# V32F20x_CM33 register map
File version: 1.0.3
CPU: CM33 r0p4, little endian, MPU, FPU, DSP, 3 interrupt priority bits, 8 SAU regions
Registers are 32-bit, read-write, reset 0x0 unless marked. A register's access mark holds for its fields unless they carry their own. Offsets are from the block's base; [hi:lo] are bit positions.

## ETH0 — ETH0 Peripheral Interface
Base 0x40202000
Same registers: ETH1 0x40204000, SEC_ETH0 0x50202000, SEC_ETH1 0x50204000
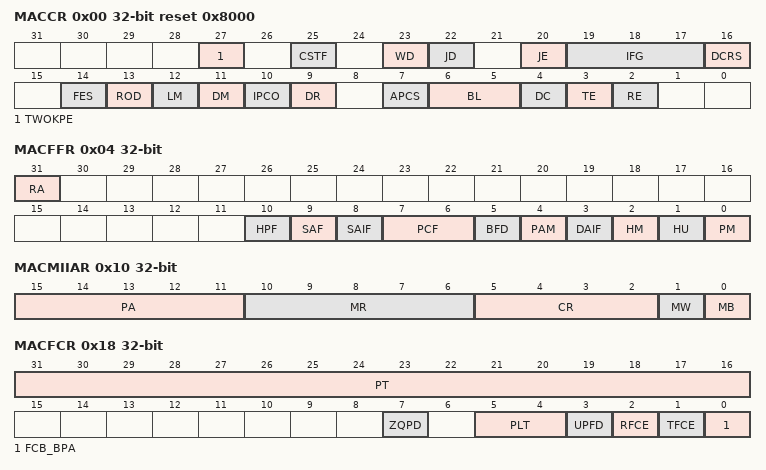
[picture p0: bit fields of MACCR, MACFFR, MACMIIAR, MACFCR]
0x00 MACCR reset 0x8000 — This is the operation mode register for the MAC.
  [27] TWOKPE — IEEE 802.3as Support for 2K Packets
  [25] CSTF — CRC Stripping for Type Frames
  [23] WD — Watchdog Disable
  [22] JD — Jabber Disable
  [20] JE — Jumbo Frame Enable
  [19:17] IFG — Inter-Frame Gap
  [16] DCRS — Disable Carrier Sense During Transmission
  [14] FES — Speed
  [13] ROD — Disable Receive Own
  [12] LM — Loopback Mode
  [11] DM — Duplex Mode
  [10] IPCO — Checksum Offload
  [9] DR — Disable Retry
  [7] APCS — Automatic Pad or CRC Stripping
  [6:5] BL — Back-Off Limit
  [4] DC — Deferral Check
  [3] TE — Transmitter Enable
  [2] RE — Receiver Enable
0x04 MACFFR — Contains the frame filtering controls.
  [31] RA — Receive All
  [10] HPF — Hash or Perfect Filter
  [9] SAF — Source Address Filter Enable
  [8] SAIF — SA Inverse Filtering
  [7:6] PCF — Pass Control Frames
  [5] BFD — Broadcast Frames Disable
  [4] PAM — Pass All Multicast
  [3] DAIF — DA Inverse Filtering
  [2] HM — Hash Multicast
  [1] HU — Hash Unicast
  [0] PM — Promiscuous Mode
0x08 MACHTHR — Contains the higher 32 bits of the Multicast Hash table
  [31:0] HTH — Hash Table High
0x0C MACHTLR — Contains the lower 32 bits of the Multicast Hash table
  [31:0] HTL — Hash Table Low
0x10 MACMIIAR — Controls the management cycles to an external PHY.
  [15:11] PA — Physical Layer Address
  [10:6] MR — MII Register
  [5:2] CR — Clock Range
  [1] MW — MII Write
  [0] MB — MII Busy
0x14 MACMIIDR — Contains the data to be written to or read from the PHY register
  [15:0] MD — MII Data
0x18 MACFCR — Controls the generation of control frames.
  [31:16] PT — Pause Time
  [7] ZQPD — Zero-Quanta Pause Disable
  [5:4] PLT — Pause Low Threshold
  [3] UPFD — Unicast Pause Frame Detect
  [2] RFCE — Receive Flow Control Enable
  [1] TFCE — Transmit Flow Control Enable
  [0] FCB_BPA — Flow Control Busy or Backpressure Activate
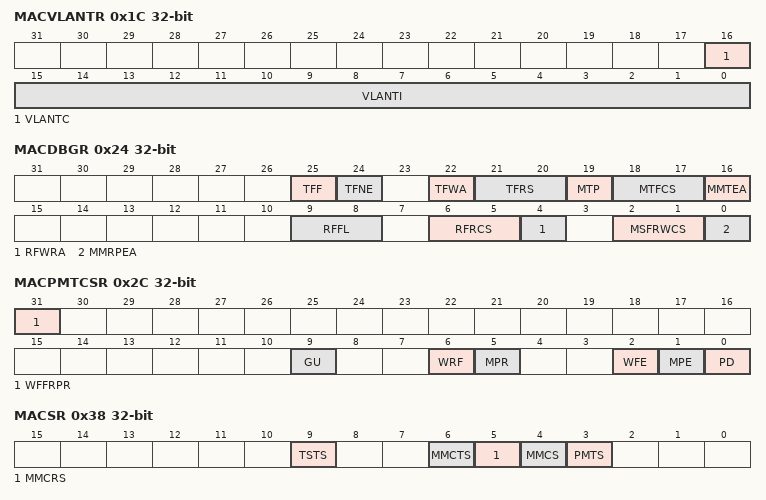
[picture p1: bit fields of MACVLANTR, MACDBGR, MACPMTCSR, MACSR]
0x1C MACVLANTR — Identifies IEEE 802.1Q VLAN type frames.
  [16] VLANTC — Enable 12-Bit VLAN Tag Comparison
  [15:0] VLANTI — VLAN Tag Identifier for Receive Frames
0x24 MACDBGR — Gives the status of various internal blocks for debugging
  [25] TFF — TxStatus FIFO Full Status
  [24] TFNE — Tx FIFO Not Empty Status
  [22] TFWA — Tx FIFO Write Controller Status
  [21:20] TFRS — Tx FIFO Read Controller Status
  [19] MTP — MAC Transmitter in Pause
  [18:17] MTFCS — MAC Transmit Frame Controller Status
  [16] MMTEA — MAC MII Transmit Protocol Engine Status
  [9:8] RFFL — RxFIFO Fill-Level Status
  [6:5] RFRCS — RxFIFO Read Controller State
  [4] RFWRA — Rx FIFO Write Controller Active Status
  [2:1] MSFRWCS — MAC Receive Frame FIFO Controller Status
  [0] MMRPEA — MAC MII Receive Protocol Engine Status
0x28 MACRWUFFR — This is the address through which the application writes or reads the remote wake-up frame filter registers
  [31:0] WF — Ethernet MAC remote wakeup frame filter register.
0x2C MACPMTCSR — Ethernet MAC PMT control and status register
  [31] WFFRPR — Wakeup frame filter register pointer reset
  [9] GU — Global unicast
  [6] WRF — Wakeup frame received
  [5] MPR — Magic packet received
  [2] WFE — Wakeup frame enable
  [1] MPE — Magic Packet enable
  [0] PD — Power down
0x38 MACSR — Contains the interrupt status.
  [9] TSTS — Timestamp Interrupt Status
  [6] MMCTS — MMC Transmit Interrupt Status
  [5] MMCRS — MMC Receive Interrupt Status
  [4] MMCS — MMC Interrupt Status
  [3] PMTS — PMT Interrupt Status
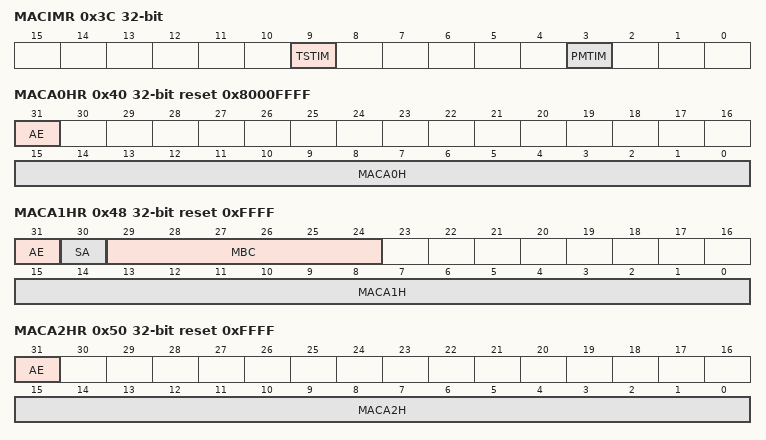
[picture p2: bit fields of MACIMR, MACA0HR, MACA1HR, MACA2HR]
0x3C MACIMR — Contains the masks for generating the interrupts.
  [9] TSTIM — Timestamp Interrupt Mask
  [3] PMTIM — PMT Interrupt Mask
0x40 MACA0HR reset 0x8000FFFF — Contains the higher 16 bits of the first MAC address
  [31] AE — Address Enable
  [15:0] MACA0H — MAC Address0 [47:32]
0x44 MACA0LR reset 0xFFFFFFFF — Contains the lower 32 bits of the first MAC address
  [31:0] MACA0L — MAC Address0 [31:0]
0x48 MACA1HR reset 0xFFFF — Contains the higher 16 bits of the second MAC address
  [31] AE — Address Enable
  [30] SA — Source Address
  [29:24] MBC — Mask Byte Control
  [15:0] MACA1H — MAC Address1 [47:32]
0x4C MACA1LR reset 0xFFFFFFFF — Contains the lower 32 bits of the second MAC address
  [31:0] MACA1L — MAC Address1 [31:0]
0x50 MACA2HR reset 0xFFFF — Contains the higher 16 bits of the third MAC address
  [31] AE — Address Enable
  [15:0] MACA2H — MAC Address2 [47:32]
0x54 MACA2LR reset 0xFFFFFFFF — Contains the lower 32 bits of the third MAC address
  [31:0] MACA2L — MAC Address2 [31:0]
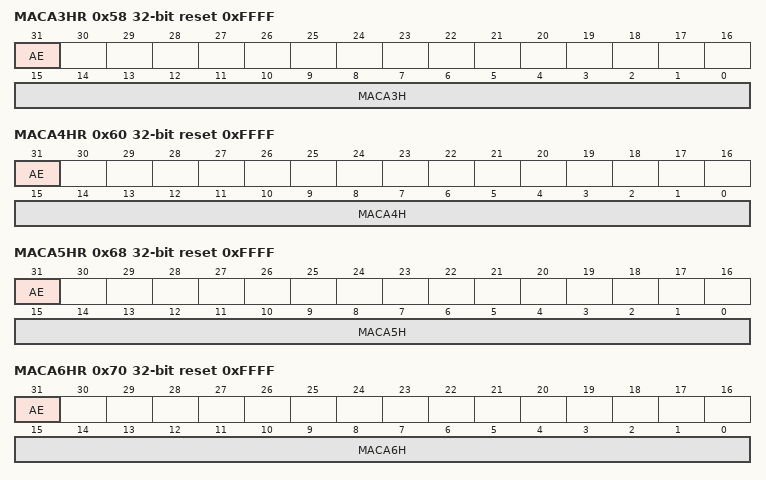
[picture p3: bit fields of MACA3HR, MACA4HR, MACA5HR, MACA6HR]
0x58 MACA3HR reset 0xFFFF — Contains the higher 16 bits of the fourth MAC address
  [31] AE — Address Enable
  [15:0] MACA3H — MAC Address3 [47:32]
0x5C MACA3LR reset 0xFFFFFFFF — Contains the lower 32 bits of the fourth MAC address
  [31:0] MACA3L — MAC Address3 [31:0]
0x60 MACA4HR reset 0xFFFF — Contains the higher 16 bits of the fifth MAC address
  [31] AE — Address Enable
  [15:0] MACA4H — MAC Address4 [47:32]
0x64 MACA4LR reset 0xFFFFFFFF — Contains the lower 32 bits of the fifth MAC address
  [31:0] MACA4L — MAC Address4 [31:0]
0x68 MACA5HR reset 0xFFFF — Contains the higher 16 bits of the sixth MAC address
  [31] AE — Address Enable
  [15:0] MACA5H — MAC Address5 [47:32]
0x6C MACA5LR reset 0xFFFFFFFF — Contains the lower 32 bits of the sixth MAC address
  [31:0] MACA5L — MAC Address5 [31:0]
0x70 MACA6HR reset 0xFFFF — Contains the higher 16 bits of the seventh MAC address
  [31] AE — Address Enable
  [15:0] MACA6H — MAC Address6 [47:32]
0x74 MACA6LR reset 0xFFFFFFFF — Contains the lower 32 bits of the seventh MAC address
  [31:0] MACA6L — MAC Address6 [31:0]
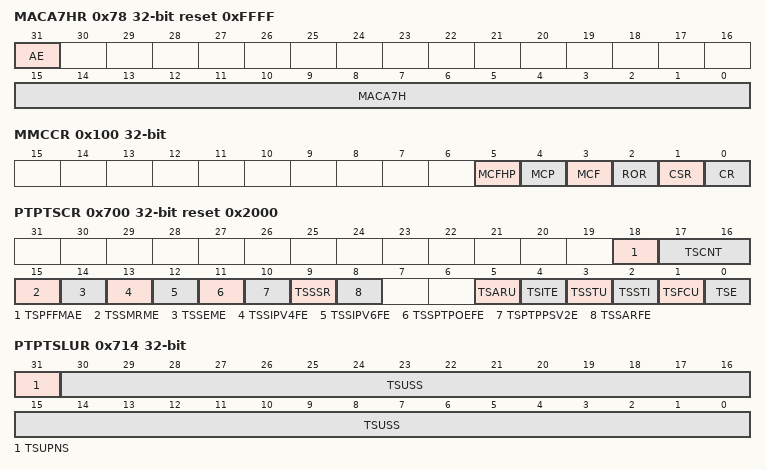
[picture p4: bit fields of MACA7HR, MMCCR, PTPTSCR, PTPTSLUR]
0x78 MACA7HR reset 0xFFFF — Contains the higher 16 bits of the eighth MAC address
  [31] AE — Address Enable
  [15:0] MACA7H — MAC Address7 [47:32]
0x7C MACA7LR reset 0xFFFFFFFF — Contains the lower 32 bits of the eighth MAC address
  [31:0] MACA7L — MAC Address7 [31:0]
0x100 MMCCR — Establishes the operating mode of the management counters
  [5] MCFHP — MMC counter Full-Half preset
  [4] MCP — MMC counter preset
  [3] MCF — MMC counter freeze
  [2] ROR — When this bit is set the MMC counters is reset to zero after read self clearing after reset
  [1] CSR — Counter stop rollover
  [0] CR — Counter reset
0x14C MMCTGFSCCR — Contains the number of successfully transmitted frames after a single collision in Half-duplex mode
  [31:0] TGFSCC — Transmitted good frames single collision counter
0x150 MMCTGFMSCCR — Contains the number of successfully transmitted frames after more than a single collision in Half-duplex mode
  [31:0] TGFMSCC — Transmitted good frames more single collision counter
0x168 MMCTGFCR — Contains the number of good frames transmitted.
  [31:0] TGFC — Transmitted good frames counter
0x194 MMCRFCECR — Contains the number of frames received with CRC error
  [31:0] RFECE — Received frames CRC error counter
0x198 MMCRFAECR — Ethernet MMC received frames with alignment error counter
  [31:0] RFAEC — Received frames alignment error counter
0x1C4 MMCRGUFCR — Contains the number of good unicast frames received
  [31:0] RGUFC — Received good unicast frames counter
0x700 PTPTSCR reset 0x2000 — Controls the timestamp generation and update logic
  [18] TSPFFMAE — Enable MAC address for PTP Frame Filtering
  [17:16] TSCNT — Select PTP packets for Taking Snapshots
  [15] TSSMRME — Enable Snapshot for Messages Relevant to Master
  [14] TSSEME — Enable Timestamp Snapshot for Event Messages
  [13] TSSIPV4FE — Enable Processing of PTP Frames Sent over IPv4 UDP
  [12] TSSIPV6FE — Enable Processing of PTP Frames Sent over IPv6 UDP
  [11] TSSPTPOEFE — Enable Processing of PTP over Ethernet Frames
  [10] TSPTPPSV2E — Enable PTP packet Processing for Version 2 Format
  [9] TSSSR — Timestamp Digital or Binary Rollover Control
  [8] TSSARFE — Enable Timestamp for All Frames
  [5] TSARU — Addend Register Update
  [4] TSITE — Timestamp Interrupt Trigger Enable
  [3] TSSTU — Timestamp Update 0
  [2] TSSTI — Timestamp Initialize
  [1] TSFCU — Timestamp Fine or Coarse Update
  [0] TSE — Timestamp Enable
0x704 PTPSSIR — Contains the 8-bit value by which the Sub-Second register is incremented
  [7:0] SSINC — Sub-second Increment Value
0x708 PTPTSHR — Contains the lower 32 bits of the seconds field of the system time
  [31:0] STS — Timestamp Second
0x70C PTPTSLR — Contains 32 bits of the nano-seconds field of the system time
  [30:0] STPNS — Timestamp Sub Seconds
0x710 PTPTSHUR — Contains the lower 32 bits of the seconds field to be written to, added to, or subtracted from the System Time value
  [31:0] TSUS — Timestamp Second
0x714 PTPTSLUR — Contains 32 bits of the nano-seconds field to be written to, added to, or subtracted from the System Time value
  [31] TSUPNS — Add or Subtract Time
  [30:0] TSUSS — Timestamp Sub Seconds
0x718 PTPTSAR — This register is used by the software to readjust the clock frequency linearly to match the master clock frequency
  [31:0] TSA — Timestamp Addend Register
0x71C PTPTTHR — Contains the higher 32 bits of time to be compared with the system time for interrupt event generation or to start the PPS signal output generation
  [31:0] TTSH — Target Time Seconds Register
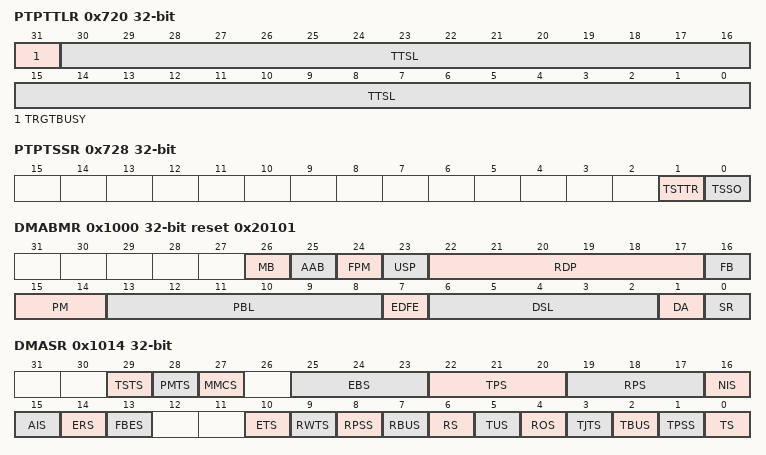
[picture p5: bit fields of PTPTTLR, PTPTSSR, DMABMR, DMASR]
0x720 PTPTTLR — Contains the lower 32 bits of time to be compared with the system time for interrupt event generation or to start the PPS signal output generation
  [31] TRGTBUSY — Target Time Register Busy
  [30:0] TTSL — Target Timestamp Low Register
0x728 PTPTSSR — Contains the PTP status.
  [1] TSTTR — Timestamp Target Time Reached
  [0] TSSO — Timestamp Seconds Overflow
0x72C PTPPPSCR — This register is used to control the interval of the PPS signal output
  [3:0] PPSFREQ — PPS0 Output Frequency Control
0x1000 DMABMR reset 0x20101 — Controls the Host Interface Mode.
  [26] MB — Mixed Burst
  [25] AAB — Address-Aligned Beats
  [24] FPM — PBLx8 Mode
  [23] USP — Use Separate
  [22:17] RDP — Rx DMA PBL
  [16] FB — Fixed Burst
  [15:14] PM — Priority Ratio
  [13:8] PBL — Programmable burst length
  [7] EDFE — Alternate Descriptor Size
  [6:2] DSL — Descriptor Skip Length
  [1] DA — DMA Arbitration
  [0] SR — Software Reset
0x1004 DMATPDR — Used by the host to instruct the DMA to poll the Transmit Descriptor list
  [31:0] TPD — Transmit Poll Demand
0x1008 DMARPDR — Used by the host to instruct the DMA to poll the Receive Descriptor list
  [31:0] RPD — Receive Poll Demand
0x100C DMARDLAR — Points the DMA to the start of the Receive Descriptor list
  [31:0] SRL — Start of Receive List
0x1010 DMATDLAR — Points the DMA to the start of the Transmit Descriptor list
  [31:0] STL — Start of Transmit List
0x1014 DMASR — The Software driver (application) reads this register during interrupt service routine or polling to determine the status of the DMA
  [29] TSTS — Time stamp trigger status
  [28] PMTS — PMT Interrupt status
  [27] MMCS — MMC Interrupt status
  [25:23] EBS — Error Bits Status
  [22:20] TPS — Transmit Process State
  [19:17] RPS — Receive Process State
  [16] NIS — Normal interrupt summary
  [15] AIS — Abnormal Interrupt Summary
  [14] ERS — Early Receive Interrupt Status
  [13] FBES — Fatal Bus Error Interrupt Status
  [10] ETS — Early Transmit Interrupt Status
  [9] RWTS — Receive Watchdog Timeout Status
  [8] RPSS — Receive Process Stopped Status
  [7] RBUS — Receive Buffer Unavailable Status
  [6] RS — Receive Interrupt Status
  [5] TUS — Transmit Underflow Status
  [4] ROS — Receive Overflow Status
  [3] TJTS — Transmit Jabber Timeout Status
  [2] TBUS — Transmit Buffer Unavailable Status
  [1] TPSS — Transmit Process Stopped Status
  [0] TS — Transmit Interrupt Status
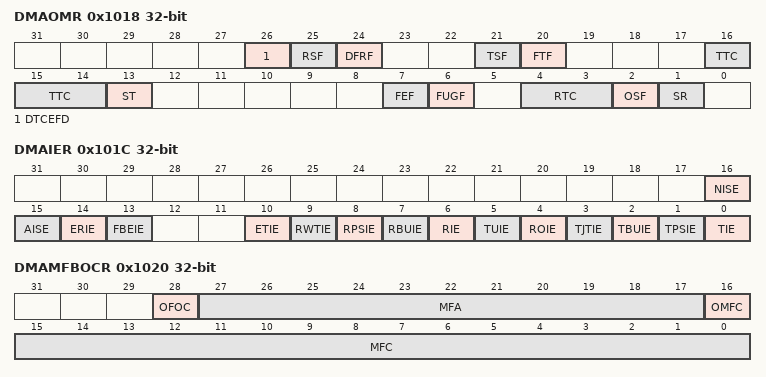
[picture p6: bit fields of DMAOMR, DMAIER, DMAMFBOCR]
0x1018 DMAOMR — Establishes the Receive and Transmit operating modes and command
  [26] DTCEFD — Disable Dropping of TCP/IP Checksum Error Frames
  [25] RSF — Receive Store and Forward
  [24] DFRF — Disable Flushing of Received Frames
  [21] TSF — Transmit Store and Forward
  [20] FTF — Flush Transmit FIFO
  [16:14] TTC — Transmit Threshold Control
  [13] ST — Start or Stop Transmission Command
  [7] FEF — Forward Error Frames
  [6] FUGF — Forward Undersized Good Frames
  [4:3] RTC — Receive Threshold Control
  [2] OSF — Operate on Second Frame
  [1] SR — Start or Stop Receive
0x101C DMAIER — Enables the interrupts reported by the Status Register
  [16] NISE — Normal Interrupt Summary Enable
  [15] AISE — Abnormal Interrupt Summary Enable
  [14] ERIE — Early Receive Interrupt Enable
  [13] FBEIE — Fatal Bus Error Enable
  [10] ETIE — Early Transmit Interrupt Enable
  [9] RWTIE — Receive Watchdog Timeout Enable
  [8] RPSIE — Receive Stopped Enable 0
  [7] RBUIE — Receive Buffer Unavailable Enable
  [6] RIE — Receive Interrupt Enable
  [5] TUIE — Underflow Interrupt Enable
  [4] ROIE — Overflow Interrupt Enable
  [3] TJTIE — Transmit Jabber Timeout Enable
  [2] TBUIE — Transmit Buffer Unavailable Enable
  [1] TPSIE — Transmit Stopped Enable
  [0] TIE — Transmit Interrupt Enable
0x1020 DMAMFBOCR — Contains the counters for discarded frames because no host Receive Descriptor was available or because of Receive FIFO Overflow
  [28] OFOC — Overflow Bit for FIFO Overflow Counter
  [27:17] MFA — Overflow Frame Counter
  [16] OMFC — Overflow Bit for Missed Frame Counter
  [15:0] MFC — Missed Frame Counter
0x1024 DMARSWTR — Watchdog timeout for Receive Status from DMA.
  [7:0] RSWTC — Receive status (RS) watchdog timer count
0x1048 DMACHTDR — Points to the start of current Transmit Descriptor read by the DMA
  [31:0] HTDAP — Host Transmit Descriptor Address Pointer
0x104C DMACHRDR — Points to the start of current Receive Descriptor read by the DMA
  [31:0] HRDAP — Host Receive Descriptor Address Pointer
0x1050 DMACHTBAR — Points to the current Transmit Buffer address read by the DMA
  [31:0] HTBAP — Host Transmit Buffer Address Pointer
0x1054 DMACHRBAR — Points to the current Receive Buffer address read by the DMA
  [31:0] HRBAP — Host Receive Buffer Address Pointer
